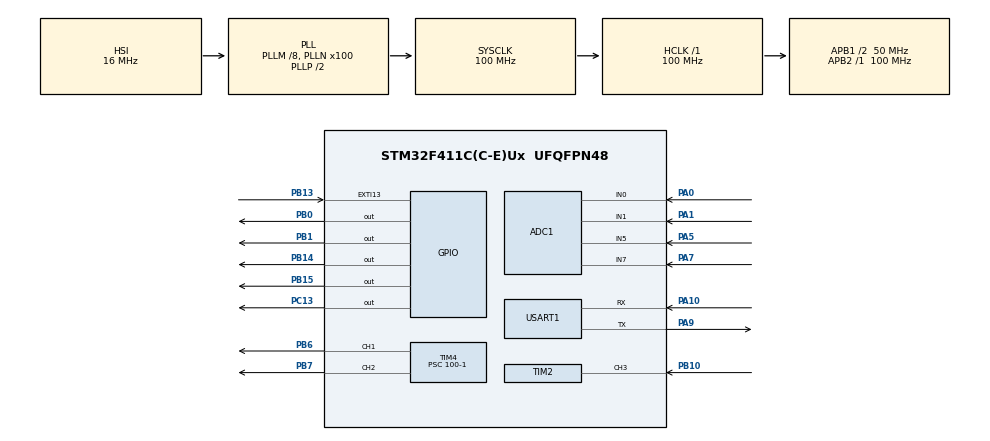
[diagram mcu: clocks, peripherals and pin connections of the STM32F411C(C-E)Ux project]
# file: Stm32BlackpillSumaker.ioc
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ADC1.Channel-28\#ChannelRegularConversion=ADC_CHANNEL_5
ADC1.Channel-29\#ChannelRegularConversion=ADC_CHANNEL_1
ADC1.ContinuousConvMode=ENABLE
ADC1.DMAContinuousRequests=ENABLE
ADC1.NbrOfConversion=2
ADC1.NbrOfConversionFlag=1
ADC1.Rank-28\#ChannelRegularConversion=1
ADC1.Rank-29\#ChannelRegularConversion=2
ADC1.SamplingTime-28\#ChannelRegularConversion=ADC_SAMPLETIME_112CYCLES
ADC1.SamplingTime-29\#ChannelRegularConversion=ADC_SAMPLETIME_112CYCLES
ADC1.ScanConvMode=ENABLE
ADC1.master=1
Dma.ADC1.0.Direction=DMA_PERIPH_TO_MEMORY
Dma.ADC1.0.FIFOMode=DMA_FIFOMODE_DISABLE
Dma.ADC1.0.Instance=DMA2_Stream0
Dma.ADC1.0.MemDataAlignment=DMA_MDATAALIGN_HALFWORD
Dma.ADC1.0.MemInc=DMA_MINC_ENABLE
Dma.ADC1.0.Mode=DMA_CIRCULAR
Dma.ADC1.0.PeriphDataAlignment=DMA_PDATAALIGN_HALFWORD
Dma.ADC1.0.PeriphInc=DMA_PINC_DISABLE
Dma.ADC1.0.Priority=DMA_PRIORITY_LOW
Dma.Request0=ADC1
Mcu.Family=STM32F4
Mcu.Name=STM32F411C(C-E)Ux
Mcu.Package=UFQFPN48
NVIC.DMA2_Stream0_IRQn=true\:0\:0\:false\:false\:true\:false\:true\:true
NVIC.EXTI15_10_IRQn=true\:0\:0\:false\:false\:true\:true\:true\:true
NVIC.PriorityGroup=NVIC_PRIORITYGROUP_4
NVIC.TIM2_IRQn=true\:0\:0\:false\:false\:true\:true\:true\:true
NVIC.USART1_IRQn=true\:0\:0\:false\:false\:true\:true\:true\:true
PA0-WKUP.Signal=ADCx_IN0
PA1.Signal=ADCx_IN1
PA10.Mode=Asynchronous
PA10.Signal=USART1_RX
PA13.Mode=Serial_Wire
PA13.Signal=SYS_JTMS-SWDIO
PA14.Mode=Serial_Wire
PA14.Signal=SYS_JTCK-SWCLK
PA5.Signal=ADCx_IN5
PA7.Signal=ADCx_IN7
PA9.Mode=Asynchronous
PA9.Signal=USART1_TX
PB0.Signal=GPIO_Output
PB1.Signal=GPIO_Output
PB10.Signal=S_TIM2_CH3
PB13.GPIO_ModeDefaultEXTI=GPIO_MODE_IT_RISING_FALLING
PB13.GPIO_PuPd=GPIO_PULLDOWN
PB13.Signal=GPXTI13
PB14.Signal=GPIO_Output
PB15.Signal=GPIO_Output
PB6.Signal=S_TIM4_CH1
PB7.Signal=S_TIM4_CH2
PC13-ANTI_TAMP.Signal=GPIO_Output
PH0\ -\ OSC_IN.Mode=HSE-External-Oscillator
PH0\ -\ OSC_IN.Signal=RCC_OSC_IN
PH1\ -\ OSC_OUT.Mode=HSE-External-Oscillator
PH1\ -\ OSC_OUT.Signal=RCC_OSC_OUT
ProjectManager.HeapSize=0x200
ProjectManager.StackSize=0x400
ProjectManager.TargetToolchain=STM32CubeIDE
RCC.48MHZClocksFreq_Value=50000000
RCC.AHBFreq_Value=100000000
RCC.APB1CLKDivider=RCC_HCLK_DIV2
RCC.APB1Freq_Value=50000000
RCC.APB1TimFreq_Value=100000000
RCC.APB2Freq_Value=100000000
RCC.APB2TimFreq_Value=100000000
RCC.CortexFreq_Value=100000000
RCC.HCLKFreq_Value=100000000
RCC.HSE_VALUE=25000000
RCC.HSI_VALUE=16000000
RCC.LSE_VALUE=32768
RCC.PLLM=8
RCC.PLLN=100
RCC.SYSCLKFreq_VALUE=100000000
RCC.SYSCLKSource=RCC_SYSCLKSOURCE_PLLCLK
RCC.VCOOutputFreq_Value=200000000
SH.ADCx_IN0.0=ADC1_IN0,IN0
SH.ADCx_IN1.0=ADC1_IN1,IN1
SH.ADCx_IN5.0=ADC1_IN5,IN5
SH.ADCx_IN7.0=ADC1_IN7,IN7
SH.S_TIM2_CH3.0=TIM2_CH3,Input_Capture3_from_TI3
SH.S_TIM4_CH1.0=TIM4_CH1,PWM Generation1 CH1
SH.S_TIM4_CH2.0=TIM4_CH2,PWM Generation2 CH2
TIM2.Channel-Input_Capture3_from_TI3=TIM_CHANNEL_3
TIM2.ICFilter_CH3=4
TIM2.ICPolarity_CH3=TIM_INPUTCHANNELPOLARITY_BOTHEDGE
TIM2.Period=0xffffffff-1
TIM2.Prescaler=99
TIM4.Channel-PWM\ Generation1\ CH1=TIM_CHANNEL_1
TIM4.Channel-PWM\ Generation2\ CH2=TIM_CHANNEL_2
TIM4.Period=20000-1
TIM4.Prescaler=100-1
USART1.VirtualMode=VM_ASYNC
VP_TIM2_VS_ClockSourceINT.Mode=Internal
board=custom

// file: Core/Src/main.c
/* USER CODE BEGIN Header */
/**
  ******************************************************************************
  * @file           : main.c
  * @brief          : Main program body
  ******************************************************************************
  * @attention
  *
  * Copyright (c) 2025 STMicroelectronics.
  * All rights reserved.
  *
  * This software is licensed under terms that can be found in the LICENSE file
  * in the root directory of this software component.
  * If no LICENSE file comes with this software, it is provided AS-IS.
  *
  ******************************************************************************
  */
/* USER CODE END Header */
#include "main.h"

/* USER CODE BEGIN Includes */

#include <maincpp.hpp> // Incluir la clase puente cpp

/* USER CODE END Includes */

ADC_HandleTypeDef hadc1;
DMA_HandleTypeDef hdma_adc1;

TIM_HandleTypeDef htim2;
TIM_HandleTypeDef htim4;

UART_HandleTypeDef huart1;

void SystemClock_Config(void);
static void MX_GPIO_Init(void);
static void MX_DMA_Init(void);
static void MX_USART1_UART_Init(void);
static void MX_ADC1_Init(void);
static void MX_TIM4_Init(void);
static void MX_TIM2_Init(void);

/* USER CODE BEGIN 0 */

//PA5 tracker left
//PA1 tracker right
//PA7 tracker distance left
//PA0 tracker distance right

//#define GYM_MODE

#define NUM_ADC_CHANNELS    7

uint16_t adc_values[NUM_ADC_CHANNELS];

/* USER CODE END 0 */

int main(void)
{

  /* MCU Configuration--------------------------------------------------------*/

  /* Reset of all peripherals, Initializes the Flash interface and the Systick. */
  HAL_Init();

  /* Configure the system clock */
  SystemClock_Config();

  /* Initialize all configured peripherals */
  MX_GPIO_Init();
  MX_DMA_Init();
  MX_USART1_UART_Init();
  MX_ADC1_Init();
  MX_TIM4_Init();
  MX_TIM2_Init();
  /* USER CODE BEGIN 2 */
  #ifdef GYM_MODE

  #else
    main_fura_mode(&htim2, &htim4,
                   &hadc1, adc_values, NUM_ADC_CHANNELS);
  #endif
  /* USER CODE END 2 */

  /* Infinite loop */
  while (1)
  {

  }
}

void SystemClock_Config(void)
{
  RCC_OscInitTypeDef RCC_OscInitStruct = {0};
  RCC_ClkInitTypeDef RCC_ClkInitStruct = {0};

  /** Configure the main internal regulator output voltage
  */
  __HAL_RCC_PWR_CLK_ENABLE();
  __HAL_PWR_VOLTAGESCALING_CONFIG(PWR_REGULATOR_VOLTAGE_SCALE1);

  /** Initializes the RCC Oscillators according to the specified parameters
  * in the RCC_OscInitTypeDef structure.
  */
  RCC_OscInitStruct.OscillatorType = RCC_OSCILLATORTYPE_HSI;
  RCC_OscInitStruct.HSIState = RCC_HSI_ON;
  RCC_OscInitStruct.HSICalibrationValue = RCC_HSICALIBRATION_DEFAULT;
  RCC_OscInitStruct.PLL.PLLState = RCC_PLL_ON;
  RCC_OscInitStruct.PLL.PLLSource = RCC_PLLSOURCE_HSI;
  RCC_OscInitStruct.PLL.PLLM = 8;
  RCC_OscInitStruct.PLL.PLLN = 100;
  RCC_OscInitStruct.PLL.PLLP = RCC_PLLP_DIV2;
  RCC_OscInitStruct.PLL.PLLQ = 4;
  if (HAL_RCC_OscConfig(&RCC_OscInitStruct) != HAL_OK)
  {
    Error_Handler();
  }

  /** Initializes the CPU, AHB and APB buses clocks
  */
  RCC_ClkInitStruct.ClockType = RCC_CLOCKTYPE_HCLK|RCC_CLOCKTYPE_SYSCLK
                              |RCC_CLOCKTYPE_PCLK1|RCC_CLOCKTYPE_PCLK2;
  RCC_ClkInitStruct.SYSCLKSource = RCC_SYSCLKSOURCE_PLLCLK;
  RCC_ClkInitStruct.AHBCLKDivider = RCC_SYSCLK_DIV1;
  RCC_ClkInitStruct.APB1CLKDivider = RCC_HCLK_DIV2;
  RCC_ClkInitStruct.APB2CLKDivider = RCC_HCLK_DIV1;

  if (HAL_RCC_ClockConfig(&RCC_ClkInitStruct, FLASH_LATENCY_3) != HAL_OK)
  {
    Error_Handler();
  }
}

static void MX_ADC1_Init(void)
{

  ADC_ChannelConfTypeDef sConfig = {0};

  /** Configure the global features of the ADC (Clock, Resolution, Data Alignment and number of conversion)
  */
  hadc1.Instance = ADC1;
  hadc1.Init.ClockPrescaler = ADC_CLOCK_SYNC_PCLK_DIV4;
  hadc1.Init.Resolution = ADC_RESOLUTION_12B;
  hadc1.Init.ScanConvMode = ENABLE;
  hadc1.Init.ContinuousConvMode = ENABLE;
  hadc1.Init.DiscontinuousConvMode = DISABLE;
  hadc1.Init.ExternalTrigConvEdge = ADC_EXTERNALTRIGCONVEDGE_NONE;
  hadc1.Init.ExternalTrigConv = ADC_SOFTWARE_START;
  hadc1.Init.DataAlign = ADC_DATAALIGN_RIGHT;
  hadc1.Init.NbrOfConversion = 2;
  hadc1.Init.DMAContinuousRequests = ENABLE;
  hadc1.Init.EOCSelection = ADC_EOC_SINGLE_CONV;
  if (HAL_ADC_Init(&hadc1) != HAL_OK)
  {
    Error_Handler();
  }

  /** Configure for the selected ADC regular channel its corresponding rank in the sequencer and its sample time.
  */
  sConfig.Channel = ADC_CHANNEL_5;
  sConfig.Rank = 1;
  sConfig.SamplingTime = ADC_SAMPLETIME_112CYCLES;
  if (HAL_ADC_ConfigChannel(&hadc1, &sConfig) != HAL_OK)
  {
    Error_Handler();
  }

  /** Configure for the selected ADC regular channel its corresponding rank in the sequencer and its sample time.
  */
  sConfig.Channel = ADC_CHANNEL_1;
  sConfig.Rank = 2;
  if (HAL_ADC_ConfigChannel(&hadc1, &sConfig) != HAL_OK)
  {
    Error_Handler();
  }

}

static void MX_TIM2_Init(void)
{

  TIM_ClockConfigTypeDef sClockSourceConfig = {0};
  TIM_MasterConfigTypeDef sMasterConfig = {0};
  TIM_IC_InitTypeDef sConfigIC = {0};

  htim2.Instance = TIM2;
  htim2.Init.Prescaler = 99;
  htim2.Init.CounterMode = TIM_COUNTERMODE_UP;
  htim2.Init.Period = 0xffffffff-1;
  htim2.Init.ClockDivision = TIM_CLOCKDIVISION_DIV1;
  htim2.Init.AutoReloadPreload = TIM_AUTORELOAD_PRELOAD_DISABLE;
  if (HAL_TIM_Base_Init(&htim2) != HAL_OK)
  {
    Error_Handler();
  }
  sClockSourceConfig.ClockSource = TIM_CLOCKSOURCE_INTERNAL;
  if (HAL_TIM_ConfigClockSource(&htim2, &sClockSourceConfig) != HAL_OK)
  {
    Error_Handler();
  }
  if (HAL_TIM_IC_Init(&htim2) != HAL_OK)
  {
    Error_Handler();
  }
  sMasterConfig.MasterOutputTrigger = TIM_TRGO_RESET;
  sMasterConfig.MasterSlaveMode = TIM_MASTERSLAVEMODE_DISABLE;
  if (HAL_TIMEx_MasterConfigSynchronization(&htim2, &sMasterConfig) != HAL_OK)
  {
    Error_Handler();
  }
  sConfigIC.ICPolarity = TIM_INPUTCHANNELPOLARITY_BOTHEDGE;
  sConfigIC.ICSelection = TIM_ICSELECTION_DIRECTTI;
  sConfigIC.ICPrescaler = TIM_ICPSC_DIV1;
  sConfigIC.ICFilter = 4;
  if (HAL_TIM_IC_ConfigChannel(&htim2, &sConfigIC, TIM_CHANNEL_3) != HAL_OK)
  {
    Error_Handler();
  }

}

static void MX_TIM4_Init(void)
{

  TIM_MasterConfigTypeDef sMasterConfig = {0};
  TIM_OC_InitTypeDef sConfigOC = {0};

  htim4.Instance = TIM4;
  htim4.Init.Prescaler = 100-1;
  htim4.Init.CounterMode = TIM_COUNTERMODE_UP;
  htim4.Init.Period = 20000-1;
  htim4.Init.ClockDivision = TIM_CLOCKDIVISION_DIV1;
  htim4.Init.AutoReloadPreload = TIM_AUTORELOAD_PRELOAD_DISABLE;
  if (HAL_TIM_PWM_Init(&htim4) != HAL_OK)
  {
    Error_Handler();
  }
  sMasterConfig.MasterOutputTrigger = TIM_TRGO_RESET;
  sMasterConfig.MasterSlaveMode = TIM_MASTERSLAVEMODE_DISABLE;
  if (HAL_TIMEx_MasterConfigSynchronization(&htim4, &sMasterConfig) != HAL_OK)
  {
    Error_Handler();
  }
  sConfigOC.OCMode = TIM_OCMODE_PWM1;
  sConfigOC.Pulse = 0;
  sConfigOC.OCPolarity = TIM_OCPOLARITY_HIGH;
  sConfigOC.OCFastMode = TIM_OCFAST_DISABLE;
  if (HAL_TIM_PWM_ConfigChannel(&htim4, &sConfigOC, TIM_CHANNEL_1) != HAL_OK)
  {
    Error_Handler();
  }
  if (HAL_TIM_PWM_ConfigChannel(&htim4, &sConfigOC, TIM_CHANNEL_2) != HAL_OK)
  {
    Error_Handler();
  }
  HAL_TIM_MspPostInit(&htim4);

}

static void MX_USART1_UART_Init(void)
{

  huart1.Instance = USART1;
  huart1.Init.BaudRate = 115200;
  huart1.Init.WordLength = UART_WORDLENGTH_8B;
  huart1.Init.StopBits = UART_STOPBITS_1;
  huart1.Init.Parity = UART_PARITY_NONE;
  huart1.Init.Mode = UART_MODE_TX_RX;
  huart1.Init.HwFlowCtl = UART_HWCONTROL_NONE;
  huart1.Init.OverSampling = UART_OVERSAMPLING_16;
  if (HAL_UART_Init(&huart1) != HAL_OK)
  {
    Error_Handler();
  }

}

static void MX_DMA_Init(void)
{

  /* DMA controller clock enable */
  __HAL_RCC_DMA2_CLK_ENABLE();

  /* DMA interrupt init */
  /* DMA2_Stream0_IRQn interrupt configuration */
  HAL_NVIC_SetPriority(DMA2_Stream0_IRQn, 0, 0);
  HAL_NVIC_EnableIRQ(DMA2_Stream0_IRQn);

}

static void MX_GPIO_Init(void)
{
  GPIO_InitTypeDef GPIO_InitStruct = {0};

  /* GPIO Ports Clock Enable */
  __HAL_RCC_GPIOC_CLK_ENABLE();
  __HAL_RCC_GPIOH_CLK_ENABLE();
  __HAL_RCC_GPIOA_CLK_ENABLE();
  __HAL_RCC_GPIOB_CLK_ENABLE();

  /*Configure GPIO pin Output Level */
  HAL_GPIO_WritePin(GPIOC, GPIO_PIN_13, GPIO_PIN_RESET);

  /*Configure GPIO pin Output Level */
  HAL_GPIO_WritePin(GPIOB, GPIO_PIN_0|GPIO_PIN_1|GPIO_PIN_14|GPIO_PIN_15, GPIO_PIN_RESET);

  /*Configure GPIO pin : PC13 */
  GPIO_InitStruct.Pin = GPIO_PIN_13;
  GPIO_InitStruct.Mode = GPIO_MODE_OUTPUT_PP;
  GPIO_InitStruct.Pull = GPIO_NOPULL;
  GPIO_InitStruct.Speed = GPIO_SPEED_FREQ_LOW;
  HAL_GPIO_Init(GPIOC, &GPIO_InitStruct);

  /*Configure GPIO pins : PB0 PB1 PB14 PB15 */
  GPIO_InitStruct.Pin = GPIO_PIN_0|GPIO_PIN_1|GPIO_PIN_14|GPIO_PIN_15;
  GPIO_InitStruct.Mode = GPIO_MODE_OUTPUT_PP;
  GPIO_InitStruct.Pull = GPIO_NOPULL;
  GPIO_InitStruct.Speed = GPIO_SPEED_FREQ_LOW;
  HAL_GPIO_Init(GPIOB, &GPIO_InitStruct);

  /*Configure GPIO pin : PB13 */
  GPIO_InitStruct.Pin = GPIO_PIN_13;
  GPIO_InitStruct.Mode = GPIO_MODE_IT_RISING_FALLING;
  GPIO_InitStruct.Pull = GPIO_PULLDOWN;
  HAL_GPIO_Init(GPIOB, &GPIO_InitStruct);

  /* EXTI interrupt init*/
  HAL_NVIC_SetPriority(EXTI15_10_IRQn, 0, 0);
  HAL_NVIC_EnableIRQ(EXTI15_10_IRQn);

}

/* USER CODE BEGIN 4 */

void HAL_UART_RxCpltCallback(UART_HandleTypeDef *huart) {

}

void HAL_GPIO_EXTI_Callback(uint16_t GPIO_Pin) {
  HAL_GPIO_EXTI_Callback_cpp(GPIO_Pin);
}

void HAL_TIM_IC_CaptureCallback(TIM_HandleTypeDef *htim) {
  HAL_TIM_IC_CaptureCallback_cpp(htim);
}
/* USER CODE END 4 */

void Error_Handler(void)
{
  __disable_irq();
  while (1)
  {
  }
}
